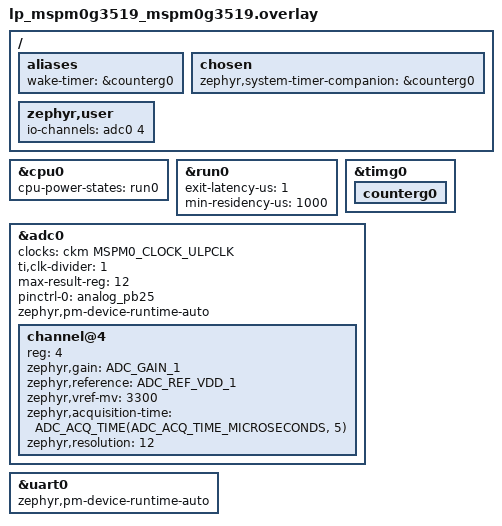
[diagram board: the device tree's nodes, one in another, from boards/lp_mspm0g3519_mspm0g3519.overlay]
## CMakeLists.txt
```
# SPDX-License-Identifier: Apache-2.0

cmake_minimum_required(VERSION 3.20.0)

find_package(Zephyr REQUIRED HINTS $ENV{ZEPHYR_BASE})
project(mspm0_adc_uart_pm)

target_sources(app PRIVATE src/main.c)
```

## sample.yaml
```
sample:
  name: MSPM0 ADC, UART, and power management
  description: Periodically sample an ADC while using RUN0/SLEEP0 and device runtime PM
common:
  tags:
    - adc
    - pm
    - uart
  platform_allow:
    - lp_mspm0g3519/mspm0g3519
    - lp_mspm0l2228/mspm0l2228
  integration_platforms:
    - lp_mspm0g3519/mspm0g3519
    - lp_mspm0l2228/mspm0l2228
  depends_on:
    - adc
    - counter
  harness: console
  harness_config:
    type: one_line
    regex:
      - "ADC0.[04]: raw=[0-9]+"
tests:
  sample.boards.ti.mspm0.adc_uart_pm: {}
```

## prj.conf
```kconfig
# SPDX-License-Identifier: Apache-2.0

CONFIG_ADC=y
CONFIG_COUNTER=y
CONFIG_SERIAL=y
CONFIG_CONSOLE=y
CONFIG_UART_CONSOLE=y
CONFIG_PRINTK=y

# Suppress periodic kernel ticks while the application is sleeping.
CONFIG_TICKLESS_KERNEL=y

# Hand system timekeeping to Timer G0 in RUN0/SLEEP0. The reset option makes
# the Cortex-M SysTick driver stop SysTick until the companion alarm wakes it.
CONFIG_SYSTEM_TIMER_LPM_COMPANION_COUNTER=y
CONFIG_SYSTEM_TIMER_RESET_BY_LPM=y
# Ensure even RUN0's sub-tick exit latency activates the companion handoff.
CONFIG_PM_PREWAKEUP_CONV_MODE_CEIL=y

# System PM selects RUN0/SLEEP0 while the application is sleeping.
CONFIG_PM=y

# ADC0 and UART0 are runtime managed by the board devicetree overlay.
CONFIG_PM_DEVICE=y
CONFIG_PM_DEVICE_RUNTIME=y

# Honor each driver's zephyr,disabling-power-states constraints while it is busy.
CONFIG_PM_POLICY_DEVICE_CONSTRAINTS=y
```

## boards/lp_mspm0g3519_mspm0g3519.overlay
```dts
/*
 * Copyright (c) 2026 Texas Instruments Incorporated
 *
 * SPDX-License-Identifier: Apache-2.0
 */

#include <zephyr/dt-bindings/adc/adc.h>

/ {
	aliases {
		wake-timer = &counterg0;
	};

	chosen {
		zephyr,system-timer-companion = &counterg0;
	};

	zephyr,user {
		io-channels = <&adc0 4>;
	};
};

&cpu0 {
	cpu-power-states = <&run0>;
};

&run0 {
	exit-latency-us = <1>;
	min-residency-us = <1000>;
};

/* Timer G0 uses 32.768 kHz LFCLK with a /256 prescaler. */
&timg0 {
	status = "okay";

	counterg0: counterg0 {
		status = "okay";
	};
};

/* ADC0.4 is available on PB25. */
&adc0 {
	clocks = <&ckm MSPM0_CLOCK_ULPCLK>;
	ti,clk-divider = <1>;
	max-result-reg = <12>;
	pinctrl-0 = <&analog_pb25>;
	pinctrl-names = "default";
	status = "okay";
	zephyr,pm-device-runtime-auto;
	#address-cells = <1>;
	#size-cells = <0>;

	channel@4 {
		reg = <4>;
		zephyr,gain = "ADC_GAIN_1";
		zephyr,reference = "ADC_REF_VDD_1";
		zephyr,vref-mv = <3300>;
		zephyr,acquisition-time = <ADC_ACQ_TIME(ADC_ACQ_TIME_MICROSECONDS, 5)>;
		zephyr,resolution = <12>;
	};
};

&uart0 {
	zephyr,pm-device-runtime-auto;
};
```

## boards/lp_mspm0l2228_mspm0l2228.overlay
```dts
/*
 * Copyright (c) 2026 Texas Instruments Incorporated
 *
 * SPDX-License-Identifier: Apache-2.0
 */

#include <zephyr/dt-bindings/adc/adc.h>

/ {
	aliases {
		wake-timer = &counterg0;
	};

	chosen {
		zephyr,system-timer-companion = &counterg0;
	};

	zephyr,user {
		io-channels = <&adc0 0>;
	};
};

&cpu0 {
	cpu-power-states = <&run0>;
};

/* Timer G0 uses ULPCLK with a /256 prescaler and /8 divider. */
&timg0 {
	ti,clk-div = <8>;
	status = "okay";

	counterg0: counterg0 {
		status = "okay";
	};
};

/* ADC0.0 is available on PA27. */
&adc0 {
	pinctrl-0 = <&analog_pa27>;
	pinctrl-names = "default";
	status = "okay";
	zephyr,pm-device-runtime-auto;
	#address-cells = <1>;
	#size-cells = <0>;

	channel@0 {
		reg = <0>;
		zephyr,gain = "ADC_GAIN_1";
		zephyr,reference = "ADC_REF_VDD_1";
		zephyr,vref-mv = <3300>;
		zephyr,acquisition-time = <ADC_ACQ_TIME(ADC_ACQ_TIME_MICROSECONDS, 4)>;
		zephyr,resolution = <12>;
	};
};

&uart0 {
	zephyr,pm-device-runtime-auto;
};
```

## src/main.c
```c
/*
 * Copyright (c) 2026 Texas Instruments Incorporated
 *
 * SPDX-License-Identifier: Apache-2.0
 */

#include <errno.h>
#include <inttypes.h>

#include <zephyr/device.h>
#include <zephyr/devicetree.h>
#include <zephyr/drivers/adc.h>
#include <zephyr/drivers/counter.h>
#include <zephyr/kernel.h>
#include <zephyr/pm/device_runtime.h>
#include <zephyr/sys/printk.h>

#define WAKE_TIMER_NODE DT_ALIAS(wake_timer)
#define SAMPLE_INTERVAL_SECONDS 3
#define SAMPLE_PERIOD           K_SECONDS(SAMPLE_INTERVAL_SECONDS)

#if !DT_NODE_HAS_PROP(DT_PATH(zephyr_user), io_channels)
#error "zephyr,user must contain an io-channels property"
#endif

static const struct adc_dt_spec adc_channel = ADC_DT_SPEC_GET(DT_PATH(zephyr_user));
static const struct device *const console = DEVICE_DT_GET(DT_CHOSEN(zephyr_console));
static const struct device *const wake_timer = DEVICE_DT_GET(WAKE_TIMER_NODE);

int main(void)
{
	uint16_t raw_value;
	struct adc_sequence sequence = {
		.buffer = &raw_value,
		.buffer_size = sizeof(raw_value),
	};
	int err;

	if (!device_is_ready(console)) {
		return -ENODEV;
	}

	if (!pm_device_runtime_is_enabled(console)) {
		printk("UART console runtime PM is not enabled\n");
		return -ENOTSUP;
	}

	if (!device_is_ready(wake_timer)) {
		printk("Wake timer is not ready\n");
		return -ENODEV;
	}

	err = counter_start(wake_timer);
	if (err < 0) {
		printk("Could not start wake timer (%d)\n", err);
		return err;
	}

	if (!adc_is_ready_dt(&adc_channel)) {
		printk("ADC controller %s is not ready\n", adc_channel.dev->name);
		return -ENODEV;
	}

	if (!pm_device_runtime_is_enabled(adc_channel.dev)) {
		printk("ADC runtime PM is not enabled\n");
		return -ENOTSUP;
	}

	err = adc_channel_setup_dt(&adc_channel);
	if (err < 0) {
		printk("ADC channel setup failed (%d)\n", err);
		return err;
	}

	err = adc_sequence_init_dt(&adc_channel, &sequence);
	if (err < 0) {
		printk("ADC sequence setup failed (%d)\n", err);
		return err;
	}

	printk("Timer G0: %u Hz; sleeping for %d seconds between ADC0 channel %u samples\n",
	       counter_get_frequency(wake_timer), SAMPLE_INTERVAL_SECONDS,
	       adc_channel.channel_id);

	while (true) {
		int32_t millivolts;

		/* System PM delegates this timeout to Timer G0 and stops SysTick. */
		k_sleep(SAMPLE_PERIOD);

		err = adc_read_dt(&adc_channel, &sequence);
		if (err < 0) {
			printk("ADC read failed (%d)\n", err);
			continue;
		}

		millivolts = raw_value;
		err = adc_raw_to_millivolts_dt(&adc_channel, &millivolts);
		if (err == 0) {
			printk("ADC0.%u: raw=%u, voltage=%" PRId32 " mV\n",
			       adc_channel.channel_id, raw_value, millivolts);
		} else {
			printk("ADC0.%u: raw=%u\n", adc_channel.channel_id, raw_value);
		}
	}

	return 0;
}
```
